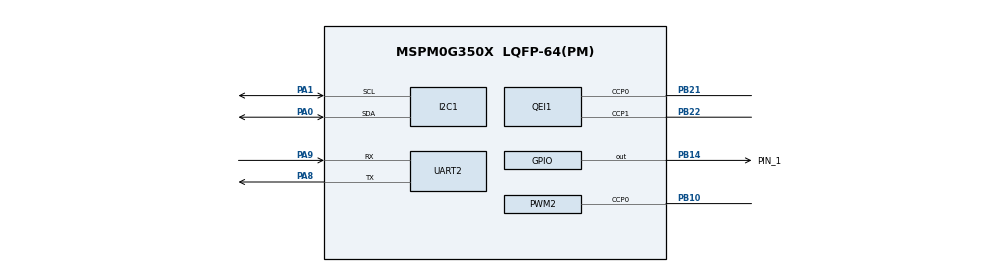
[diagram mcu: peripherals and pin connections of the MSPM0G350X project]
/**
 * These arguments were used when this file was generated. They will be automatically applied on subsequent loads
 * via the GUI or CLI. Run CLI with '--help' for additional information on how to override these arguments.
 * @cliArgs --device "MSPM0G350X" --package "LQFP-64(PM)" --part "Default" --product "mspm0_sdk@1.30.00.03"
 * @versions {"tool":"1.19.0+3426"}
 */

/**
 * Import the modules used in this configuration.
 */
const ADC12  = scripting.addModule("/ti/driverlib/ADC12", {}, false);
const ADC121 = ADC12.addInstance();
const GPIO   = scripting.addModule("/ti/driverlib/GPIO", {}, false);
const GPIO1  = GPIO.addInstance();
const GPIO2  = GPIO.addInstance();
const GPIO3  = GPIO.addInstance();
const GPIO4  = GPIO.addInstance();
const GPIO5  = GPIO.addInstance();
const GPIO6  = GPIO.addInstance();
const GPIO7  = GPIO.addInstance();
const GPIO8  = GPIO.addInstance();
const GPIO9  = GPIO.addInstance();
const I2C    = scripting.addModule("/ti/driverlib/I2C", {}, false);
const I2C1   = I2C.addInstance();
const PWM    = scripting.addModule("/ti/driverlib/PWM", {}, false);
const PWM1   = PWM.addInstance();
const PWM2   = PWM.addInstance();
const QEI    = scripting.addModule("/ti/driverlib/QEI", {}, false);
const QEI1   = QEI.addInstance();
const SYSCTL = scripting.addModule("/ti/driverlib/SYSCTL");
const UART   = scripting.addModule("/ti/driverlib/UART", {}, false);
const UART1  = UART.addInstance();
const UART2  = UART.addInstance();

/**
 * Write custom configuration values to the imported modules.
 */
ADC121.$name                             = "GRAYSCALE_ADC";
ADC121.sampClkSrc                        = "DL_ADC12_CLOCK_ULPCLK";
ADC121.sampClkDiv                        = "DL_ADC12_CLOCK_DIVIDE_8";
ADC121.sampleTime0                       = "125 us";
ADC121.powerDownMode                     = "DL_ADC12_POWER_DOWN_MODE_MANUAL";
ADC121.peripheral.$assign                = "ADC0";
ADC121.peripheral.adcPin0.$assign        = "PA27";
ADC121.adcPin0Config.hideOutputInversion = scripting.forceWrite(false);
ADC121.adcPin0Config.$name               = "ti_driverlib_gpio_GPIOPinGeneric8";

const Board = scripting.addModule("/ti/driverlib/Board", {}, false);

GPIO1.$name                         = "Monitor_Dir";
GPIO1.port                          = "PORTA";
GPIO1.associatedPins.create(2);
GPIO1.associatedPins[0].$name       = "Monitor_AIN1";
GPIO1.associatedPins[0].assignedPin = "22";
GPIO1.associatedPins[1].$name       = "Monitor_AIN2";
GPIO1.associatedPins[1].assignedPin = "15";

GPIO2.$name                         = "GPIO_GRP_1";
GPIO2.associatedPins[0].$name       = "PIN_1";
GPIO2.associatedPins[0].pin.$assign = "PB14";

GPIO3.$name                         = "Right_Motor_Dir";
GPIO3.port                          = "PORTB";
GPIO3.associatedPins.create(2);
GPIO3.associatedPins[0].$name       = "AIN1";
GPIO3.associatedPins[0].assignedPin = "0";
GPIO3.associatedPins[1].$name       = "AIN2";
GPIO3.associatedPins[1].assignedPin = "11";

GPIO4.$name                         = "Grayscale_ADDR_A";
GPIO4.port                          = "PORTA";
GPIO4.associatedPins.create(2);
GPIO4.associatedPins[0].$name       = "AD0";
GPIO4.associatedPins[0].assignedPin = "26";
GPIO4.associatedPins[1].$name       = "AD1";
GPIO4.associatedPins[1].assignedPin = "24";

GPIO5.$name                         = "Grayscale_ADDR_B";
GPIO5.port                          = "PORTB";
GPIO5.associatedPins[0].$name       = "AD2";
GPIO5.associatedPins[0].assignedPin = "24";

GPIO6.$name                              = "Key_Group";
GPIO6.port                               = "PORTB";
GPIO6.associatedPins.create(3);
GPIO6.associatedPins[0].$name            = "KEY1";
GPIO6.associatedPins[0].assignedPin      = "15";
GPIO6.associatedPins[0].direction        = "INPUT";
GPIO6.associatedPins[0].internalResistor = "PULL_UP";
GPIO6.associatedPins[1].$name            = "KEY2";
GPIO6.associatedPins[1].assignedPin      = "16";
GPIO6.associatedPins[1].direction        = "INPUT";
GPIO6.associatedPins[1].internalResistor = "PULL_UP";
GPIO6.associatedPins[2].$name            = "KEY3";
GPIO6.associatedPins[2].assignedPin      = "2";
GPIO6.associatedPins[2].direction        = "INPUT";
GPIO6.associatedPins[2].internalResistor = "PULL_UP";

GPIO7.$name                              = "Key_PA30";
GPIO7.port                               = "PORTA";
GPIO7.associatedPins[0].$name            = "KEY4";
GPIO7.associatedPins[0].assignedPin      = "30";
GPIO7.associatedPins[0].direction        = "INPUT";
GPIO7.associatedPins[0].internalResistor = "PULL_UP";

GPIO8.$name                         = "Led_Group";
GPIO8.port                          = "PORTB";
GPIO8.associatedPins.create(4);
GPIO8.associatedPins[0].$name       = "LED1";
GPIO8.associatedPins[0].assignedPin = "4";
GPIO8.associatedPins[1].$name       = "LED2";
GPIO8.associatedPins[1].assignedPin = "5";
GPIO8.associatedPins[2].$name       = "LED3";
GPIO8.associatedPins[2].assignedPin = "7";
GPIO8.associatedPins[3].$name       = "LED4";
GPIO8.associatedPins[3].assignedPin = "9";

GPIO9.$name                              = "Right_Encoder";
GPIO9.port                               = "PORTB";
GPIO9.associatedPins.create(2);
GPIO9.associatedPins[0].$name            = "PHA";
GPIO9.associatedPins[0].assignedPin      = "12";
GPIO9.associatedPins[0].direction        = "INPUT";
GPIO9.associatedPins[0].internalResistor = "PULL_UP";
GPIO9.associatedPins[0].interruptEn      = true;
GPIO9.associatedPins[0].polarity         = "RISE_FALL";
GPIO9.associatedPins[1].$name            = "PHB";
GPIO9.associatedPins[1].assignedPin      = "13";
GPIO9.associatedPins[1].direction        = "INPUT";
GPIO9.associatedPins[1].internalResistor = "PULL_UP";

I2C1.$name                             = "MPU6050_I2C";
I2C1.basicControllerStandardBusSpeed   = "Fast";
I2C1.peripheral.$assign                = "I2C0";
I2C1.peripheral.sdaPin.$assign         = "PA0";
I2C1.peripheral.sclPin.$assign         = "PA1";
I2C1.sdaPinConfig.hideOutputInversion  = scripting.forceWrite(false);
I2C1.sdaPinConfig.onlyInternalResistor = scripting.forceWrite(false);
I2C1.sdaPinConfig.passedPeripheralType = scripting.forceWrite("Digital");
I2C1.sdaPinConfig.$name                = "ti_driverlib_gpio_GPIOPinGeneric9";
I2C1.sclPinConfig.hideOutputInversion  = scripting.forceWrite(false);
I2C1.sclPinConfig.onlyInternalResistor = scripting.forceWrite(false);
I2C1.sclPinConfig.passedPeripheralType = scripting.forceWrite("Digital");
I2C1.sclPinConfig.$name                = "ti_driverlib_gpio_GPIOPinGeneric10";

PWM1.$name                              = "Monitor_Left_Timer";
PWM1.timerStartTimer                    = true;
PWM1.clockDivider                       = 8;
PWM1.timerCount                         = 100;
PWM1.ccIndex                            = [0];
PWM1.peripheral.$assign                 = "TIMG7";
PWM1.PWM_CHANNEL_0.$name                = "ti_driverlib_pwm_PWMTimerCC0";
PWM1.ccp0PinConfig.direction            = scripting.forceWrite("OUTPUT");
PWM1.ccp0PinConfig.hideOutputInversion  = scripting.forceWrite(false);
PWM1.ccp0PinConfig.onlyInternalResistor = scripting.forceWrite(false);
PWM1.ccp0PinConfig.passedPeripheralType = scripting.forceWrite("Digital");
PWM1.ccp0PinConfig.$name                = "ti_driverlib_gpio_GPIOPinGeneric0";

PWM2.$name                              = "Right_Motor_Timer";
PWM2.timerStartTimer                    = true;
PWM2.clockDivider                       = 8;
PWM2.timerCount                         = 100;
PWM2.ccIndex                            = [0];
PWM2.peripheral.$assign                 = "TIMG6";
PWM2.peripheral.ccp0Pin.$assign         = "PB10";
PWM2.PWM_CHANNEL_0.$name                = "ti_driverlib_pwm_PWMTimerCC1";
PWM2.ccp0PinConfig.direction            = scripting.forceWrite("OUTPUT");
PWM2.ccp0PinConfig.hideOutputInversion  = scripting.forceWrite(false);
PWM2.ccp0PinConfig.onlyInternalResistor = scripting.forceWrite(false);
PWM2.ccp0PinConfig.passedPeripheralType = scripting.forceWrite("Digital");
PWM2.ccp0PinConfig.$name                = "ti_driverlib_gpio_GPIOPinGeneric3";

QEI1.$name                              = "Encoder_Timer";
QEI1.timerStartTimer                    = true;
QEI1.peripheral.ccp0Pin.$assign         = "PB21";
QEI1.peripheral.ccp1Pin.$assign         = "PB22";
QEI1.ccp0PinConfig.hideOutputInversion  = scripting.forceWrite(false);
QEI1.ccp0PinConfig.onlyInternalResistor = scripting.forceWrite(false);
QEI1.ccp0PinConfig.passedPeripheralType = scripting.forceWrite("Digital");
QEI1.ccp0PinConfig.$name                = "ti_driverlib_gpio_GPIOPinGeneric1";
QEI1.ccp1PinConfig.hideOutputInversion  = scripting.forceWrite(false);
QEI1.ccp1PinConfig.onlyInternalResistor = scripting.forceWrite(false);
QEI1.ccp1PinConfig.passedPeripheralType = scripting.forceWrite("Digital");
QEI1.ccp1PinConfig.$name                = "ti_driverlib_gpio_GPIOPinGeneric2";

SYSCTL.forceDefaultClkConfig = true;
SYSCTL.clockTreeEn           = true;

UART1.$name                             = "UART_Debug";
UART1.targetBaudRate                    = 115200;
UART1.enableFIFO                        = true;
UART1.rxFifoThreshold                   = "DL_UART_RX_FIFO_LEVEL_1_4_FULL";
UART1.rxTimeoutValue                    = 15;
UART1.enabledDMARXTriggers              = "DL_UART_DMA_INTERRUPT_RX";
UART1.enabledDMATXTriggers              = "DL_UART_DMA_INTERRUPT_TX";
UART1.enabledInterrupts                 = ["RX_TIMEOUT_ERROR"];
UART1.peripheral.$assign                = "UART0";
UART1.txPinConfig.direction             = scripting.forceWrite("OUTPUT");
UART1.txPinConfig.hideOutputInversion   = scripting.forceWrite(false);
UART1.txPinConfig.onlyInternalResistor  = scripting.forceWrite(false);
UART1.txPinConfig.passedPeripheralType  = scripting.forceWrite("Digital");
UART1.txPinConfig.$name                 = "ti_driverlib_gpio_GPIOPinGeneric6";
UART1.rxPinConfig.hideOutputInversion   = scripting.forceWrite(false);
UART1.rxPinConfig.onlyInternalResistor  = scripting.forceWrite(false);
UART1.rxPinConfig.passedPeripheralType  = scripting.forceWrite("Digital");
UART1.rxPinConfig.$name                 = "ti_driverlib_gpio_GPIOPinGeneric7";
UART1.DMA_CHANNEL_RX.$name              = "DMA_CH0";
UART1.DMA_CHANNEL_RX.addressMode        = "f2b";
UART1.DMA_CHANNEL_RX.srcLength          = "BYTE";
UART1.DMA_CHANNEL_RX.dstLength          = "BYTE";
UART1.DMA_CHANNEL_RX.peripheral.$assign = "DMA_CH0";
UART1.DMA_CHANNEL_TX.$name              = "DMA_CH1";
UART1.DMA_CHANNEL_TX.addressMode        = "b2f";
UART1.DMA_CHANNEL_TX.srcLength          = "BYTE";
UART1.DMA_CHANNEL_TX.dstLength          = "BYTE";
UART1.DMA_CHANNEL_TX.enableInterrupt    = true;
UART1.DMA_CHANNEL_TX.peripheral.$assign = "DMA_CH1";

UART2.$name                             = "UART_ESP01S";
UART2.targetBaudRate                    = 115200;
UART2.enableFIFO                        = true;
UART2.rxFifoThreshold                   = "DL_UART_RX_FIFO_LEVEL_1_4_FULL";
UART2.rxTimeoutValue                    = 15;
UART2.enabledDMARXTriggers              = "DL_UART_DMA_INTERRUPT_RX";
UART2.enabledDMATXTriggers              = "DL_UART_DMA_INTERRUPT_TX";
UART2.enabledInterrupts                 = ["RX_TIMEOUT_ERROR"];
UART2.peripheral.$assign                = "UART1";
UART2.peripheral.rxPin.$assign          = "PA9";
UART2.peripheral.txPin.$assign          = "PA8";
UART2.txPinConfig.$name                 = "ti_driverlib_gpio_GPIOPinGeneric11";
UART2.txPinConfig.direction             = scripting.forceWrite("OUTPUT");
UART2.txPinConfig.hideOutputInversion   = scripting.forceWrite(false);
UART2.txPinConfig.onlyInternalResistor  = scripting.forceWrite(false);
UART2.txPinConfig.passedPeripheralType  = scripting.forceWrite("Digital");
UART2.rxPinConfig.$name                 = "ti_driverlib_gpio_GPIOPinGeneric12";
UART2.rxPinConfig.hideOutputInversion   = scripting.forceWrite(false);
UART2.rxPinConfig.onlyInternalResistor  = scripting.forceWrite(false);
UART2.rxPinConfig.passedPeripheralType  = scripting.forceWrite("Digital");
UART2.rxPinConfig.enableConfig          = true;
UART2.rxPinConfig.internalResistor      = "PULL_UP";
UART2.DMA_CHANNEL_RX.$name              = "DMA_CH2";
UART2.DMA_CHANNEL_RX.addressMode        = "f2b";
UART2.DMA_CHANNEL_RX.srcLength          = "BYTE";
UART2.DMA_CHANNEL_RX.dstLength          = "BYTE";
UART2.DMA_CHANNEL_RX.peripheral.$assign = "DMA_CH2";
UART2.DMA_CHANNEL_TX.$name              = "DMA_CH3";
UART2.DMA_CHANNEL_TX.addressMode        = "b2f";
UART2.DMA_CHANNEL_TX.srcLength          = "BYTE";
UART2.DMA_CHANNEL_TX.dstLength          = "BYTE";
UART2.DMA_CHANNEL_TX.enableInterrupt    = true;
UART2.DMA_CHANNEL_TX.peripheral.$assign = "DMA_CH3";

/**
 * Pinmux solution for unlocked pins/peripherals. This ensures that minor changes to the automatic solver in a future
 * version of the tool will not impact the pinmux you originally saw.  These lines can be completely deleted in order to
 * re-solve from scratch.
 */
Board.peripheral.$suggestSolution            = "DEBUGSS";
Board.peripheral.swclkPin.$suggestSolution   = "PA20";
Board.peripheral.swdioPin.$suggestSolution   = "PA19";
GPIO1.associatedPins[0].pin.$suggestSolution = "PA22";
GPIO1.associatedPins[1].pin.$suggestSolution = "PA15";
GPIO3.associatedPins[0].pin.$suggestSolution = "PB0";
GPIO3.associatedPins[1].pin.$suggestSolution = "PB11";
GPIO4.associatedPins[0].pin.$suggestSolution = "PA26";
GPIO4.associatedPins[1].pin.$suggestSolution = "PA24";
GPIO5.associatedPins[0].pin.$suggestSolution = "PB24";
GPIO6.associatedPins[0].pin.$suggestSolution = "PB15";
GPIO6.associatedPins[1].pin.$suggestSolution = "PB16";
GPIO6.associatedPins[2].pin.$suggestSolution = "PB2";
GPIO7.associatedPins[0].pin.$suggestSolution = "PA30";
GPIO8.associatedPins[0].pin.$suggestSolution = "PB4";
GPIO8.associatedPins[1].pin.$suggestSolution = "PB5";
GPIO8.associatedPins[2].pin.$suggestSolution = "PB7";
GPIO8.associatedPins[3].pin.$suggestSolution = "PB9";
GPIO9.associatedPins[0].pin.$suggestSolution = "PB12";
GPIO9.associatedPins[1].pin.$suggestSolution = "PB13";
PWM1.peripheral.ccp0Pin.$suggestSolution     = "PA17";
QEI1.peripheral.$suggestSolution             = "TIMG8";
UART1.peripheral.rxPin.$suggestSolution      = "PA11";
UART1.peripheral.txPin.$suggestSolution      = "PA10";
